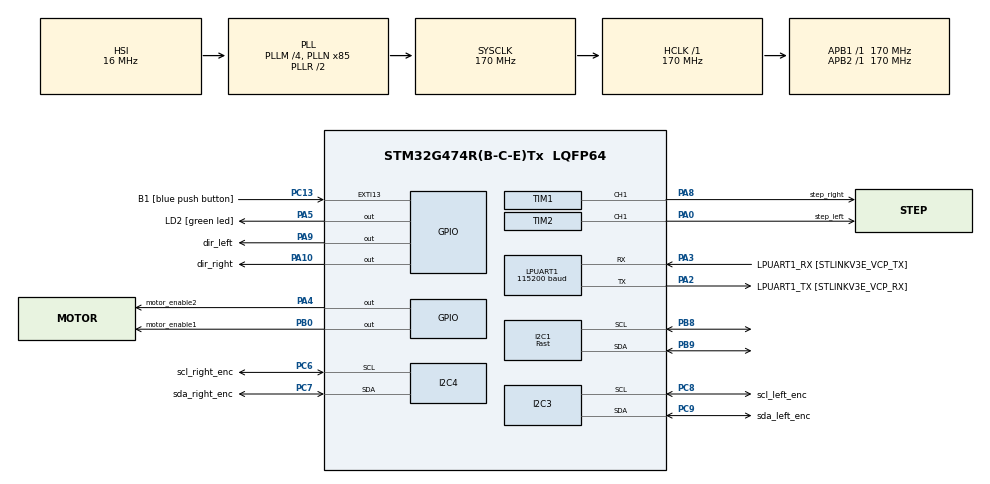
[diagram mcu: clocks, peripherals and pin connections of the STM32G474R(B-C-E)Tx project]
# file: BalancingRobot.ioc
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Dma.I2C1_RX.0.Direction=DMA_PERIPH_TO_MEMORY
Dma.I2C1_RX.0.EventEnable=DISABLE
Dma.I2C1_RX.0.Instance=DMA1_Channel1
Dma.I2C1_RX.0.MemDataAlignment=DMA_MDATAALIGN_BYTE
Dma.I2C1_RX.0.MemInc=DMA_MINC_ENABLE
Dma.I2C1_RX.0.Mode=DMA_NORMAL
Dma.I2C1_RX.0.PeriphDataAlignment=DMA_PDATAALIGN_BYTE
Dma.I2C1_RX.0.PeriphInc=DMA_PINC_DISABLE
Dma.I2C1_RX.0.Polarity=HAL_DMAMUX_REQ_GEN_RISING
Dma.I2C1_RX.0.Priority=DMA_PRIORITY_LOW
Dma.I2C1_RX.0.RequestNumber=1
Dma.I2C1_RX.0.SignalID=NONE
Dma.I2C1_RX.0.SyncEnable=DISABLE
Dma.I2C1_RX.0.SyncPolarity=HAL_DMAMUX_SYNC_NO_EVENT
Dma.I2C1_RX.0.SyncRequestNumber=1
Dma.I2C1_RX.0.SyncSignalID=NONE
Dma.LPUART1_RX.1.Direction=DMA_PERIPH_TO_MEMORY
Dma.LPUART1_RX.1.EventEnable=DISABLE
Dma.LPUART1_RX.1.Instance=DMA1_Channel2
Dma.LPUART1_RX.1.MemDataAlignment=DMA_MDATAALIGN_BYTE
Dma.LPUART1_RX.1.MemInc=DMA_MINC_ENABLE
Dma.LPUART1_RX.1.Mode=DMA_CIRCULAR
Dma.LPUART1_RX.1.PeriphDataAlignment=DMA_PDATAALIGN_BYTE
Dma.LPUART1_RX.1.PeriphInc=DMA_PINC_DISABLE
Dma.LPUART1_RX.1.Polarity=HAL_DMAMUX_REQ_GEN_RISING
Dma.LPUART1_RX.1.Priority=DMA_PRIORITY_LOW
Dma.LPUART1_RX.1.RequestNumber=1
Dma.LPUART1_RX.1.SignalID=NONE
Dma.LPUART1_RX.1.SyncEnable=DISABLE
Dma.LPUART1_RX.1.SyncPolarity=HAL_DMAMUX_SYNC_NO_EVENT
Dma.LPUART1_RX.1.SyncRequestNumber=1
Dma.LPUART1_RX.1.SyncSignalID=NONE
Dma.LPUART1_TX.2.Direction=DMA_MEMORY_TO_PERIPH
Dma.LPUART1_TX.2.EventEnable=DISABLE
Dma.LPUART1_TX.2.Instance=DMA1_Channel3
Dma.LPUART1_TX.2.MemDataAlignment=DMA_MDATAALIGN_BYTE
Dma.LPUART1_TX.2.MemInc=DMA_MINC_ENABLE
Dma.LPUART1_TX.2.Mode=DMA_NORMAL
Dma.LPUART1_TX.2.PeriphDataAlignment=DMA_PDATAALIGN_BYTE
Dma.LPUART1_TX.2.PeriphInc=DMA_PINC_DISABLE
Dma.LPUART1_TX.2.Polarity=HAL_DMAMUX_REQ_GEN_RISING
Dma.LPUART1_TX.2.Priority=DMA_PRIORITY_LOW
Dma.LPUART1_TX.2.RequestNumber=1
Dma.LPUART1_TX.2.SignalID=NONE
Dma.LPUART1_TX.2.SyncEnable=DISABLE
Dma.LPUART1_TX.2.SyncPolarity=HAL_DMAMUX_SYNC_NO_EVENT
Dma.LPUART1_TX.2.SyncRequestNumber=1
Dma.LPUART1_TX.2.SyncSignalID=NONE
Dma.Request0=I2C1_RX
Dma.Request1=LPUART1_RX
Dma.Request2=LPUART1_TX
I2C1.I2C_Speed_Mode=I2C_Fast
I2C1.Timing=0x10802D9B
I2C3.Timing=0x30A0A7FB
I2C4.Timing=0x30A0A7FB
IWDG.Prescaler=IWDG_PRESCALER_32
IWDG.Reload=99
IWDG.Window=4095
LPUART1.BaudRate=115200
LPUART1.WordLength=UART_WORDLENGTH_8B
Mcu.Family=STM32G4
Mcu.Name=STM32G474R(B-C-E)Tx
Mcu.Package=LQFP64
NVIC.DMA1_Channel1_IRQn=true\:2\:0\:true\:false\:true\:false\:true\:true
NVIC.DMA1_Channel2_IRQn=true\:3\:0\:true\:false\:true\:false\:true\:true
NVIC.DMA1_Channel3_IRQn=true\:3\:0\:true\:false\:true\:false\:true\:true
NVIC.EXTI15_10_IRQn=true\:4\:0\:true\:false\:true\:true\:true\:true
NVIC.I2C1_ER_IRQn=true\:2\:0\:true\:false\:true\:true\:true\:true
NVIC.I2C1_EV_IRQn=true\:2\:0\:true\:false\:true\:true\:true\:true
NVIC.I2C3_ER_IRQn=true\:3\:0\:true\:false\:true\:true\:true\:true
NVIC.I2C3_EV_IRQn=true\:3\:0\:true\:false\:true\:true\:true\:true
NVIC.I2C4_ER_IRQn=true\:3\:0\:true\:false\:true\:true\:true\:true
NVIC.I2C4_EV_IRQn=true\:3\:0\:true\:false\:true\:true\:true\:true
NVIC.LPUART1_IRQn=true\:3\:0\:true\:false\:true\:true\:true\:true
NVIC.PriorityGroup=NVIC_PRIORITYGROUP_4
NVIC.TIM6_DAC_IRQn=true\:1\:0\:true\:false\:true\:true\:true\:true
PA0.GPIO_Label=step_left
PA0.Signal=S_TIM2_CH1
PA10.GPIO_Label=dir_right
PA10.Signal=GPIO_Output
PA13.GPIO_Label=T_SWDIO
PA13.Mode=Serial_Wire
PA13.Signal=SYS_JTMS-SWDIO
PA14.GPIO_Label=T_SWCLK
PA14.Mode=Serial_Wire
PA14.Signal=SYS_JTCK-SWCLK
PA2.GPIO_Label=LPUART1_TX [STLINKV3E_VCP_RX]
PA2.Mode=Asynchronous
PA2.Signal=LPUART1_TX
PA3.GPIO_Label=LPUART1_RX [STLINKV3E_VCP_TX]
PA3.Mode=Asynchronous
PA3.Signal=LPUART1_RX
PA4.GPIO_Label=motor_enable2
PA4.Signal=GPIO_Output
PA5.GPIO_Label=LD2 [green led]
PA5.Signal=GPIO_Output
PA8.GPIO_Label=step_right
PA8.Signal=S_TIM1_CH1
PA9.GPIO_Label=dir_left
PA9.Signal=GPIO_Output
PB0.GPIO_Label=motor_enable1
PB0.PinState=GPIO_PIN_SET
PB0.Signal=GPIO_Output
PB3.GPIO_Label=T_SWO
PB3.Signal=SYS_JTDO-SWO
PB8-BOOT0.Mode=I2C
PB8-BOOT0.Signal=I2C1_SCL
PB9.Mode=I2C
PB9.Signal=I2C1_SDA
PC13.GPIO_Label=B1 [blue push button]
PC13.Signal=GPXTI13
PC14-OSC32_IN.Mode=LSE-External-Oscillator
PC14-OSC32_IN.Signal=RCC_OSC32_IN
PC15-OSC32_OUT.Mode=LSE-External-Oscillator
PC15-OSC32_OUT.Signal=RCC_OSC32_OUT
PC6.GPIO_Label=scl_right_enc
PC6.GPIO_Pu=GPIO_PULLUP
PC6.Mode=I2C
PC6.Signal=I2C4_SCL
PC7.GPIO_Label=sda_right_enc
PC7.GPIO_Pu=GPIO_PULLUP
PC7.Mode=I2C
PC7.Signal=I2C4_SDA
PC8.GPIO_Label=scl_left_enc
PC8.GPIO_Pu=GPIO_PULLUP
PC8.Mode=I2C
PC8.Signal=I2C3_SCL
PC9.GPIO_Label=sda_left_enc
PC9.GPIO_Pu=GPIO_PULLUP
PC9.Mode=I2C
PC9.Signal=I2C3_SDA
PF0-OSC_IN.Mode=HSE-External-Oscillator
PF0-OSC_IN.Signal=RCC_OSC_IN
PF1-OSC_OUT.Mode=HSE-External-Oscillator
PF1-OSC_OUT.Signal=RCC_OSC_OUT
ProjectManager.HeapSize=0x200
ProjectManager.StackSize=0x400
ProjectManager.TargetToolchain=STM32CubeIDE
RCC.ADC12Freq_Value=170000000
RCC.ADC345Freq_Value=170000000
RCC.AHBFreq_Value=170000000
RCC.APB1Freq_Value=170000000
RCC.APB1TimFreq_Value=170000000
RCC.APB2Freq_Value=170000000
RCC.APB2TimFreq_Value=170000000
RCC.CortexFreq_Value=170000000
RCC.EXTERNAL_CLOCK_VALUE=12288000
RCC.HCLKFreq_Value=170000000
RCC.HSE_VALUE=24000000
RCC.HSI48_VALUE=48000000
RCC.HSI_VALUE=16000000
RCC.PLLM=RCC_PLLM_DIV4
RCC.PLLN=85
RCC.RTCClockSelection=RCC_RTCCLKSOURCE_LSE
RCC.SYSCLKFreq_VALUE=170000000
RCC.SYSCLKSource=RCC_SYSCLKSOURCE_PLLCLK
RCC.USBFreq_Value=170000000
RCC.VCOOutputFreq_Value=340000000
SH.S_TIM1_CH1.0=TIM1_CH1,PWM Generation1 CH1
SH.S_TIM2_CH1.0=TIM2_CH1,PWM Generation1 CH1
TIM1.AutoReloadPreload=TIM_AUTORELOAD_PRELOAD_ENABLE
TIM1.Channel-PWM\ Generation1\ CH1=TIM_CHANNEL_1
TIM1.PeriodNoDither=999
TIM1.Prescaler=169
TIM2.AutoReloadPreload=TIM_AUTORELOAD_PRELOAD_ENABLE
TIM2.Channel-PWM\ Generation1\ CH1=TIM_CHANNEL_1
TIM2.PeriodNoDither=999
TIM2.Prescaler=169
TIM6.PeriodNoDither=1999
TIM6.Prescaler=169
VP_IWDG_VS_IWDG.Mode=IWDG_Activate
VP_SYS_VS_DBSignals.Mode=DisableDeadBatterySignals
VP_TIM1_VS_ClockSourceINT.Mode=Internal
VP_TIM2_VS_ClockSourceINT.Mode=Internal
VP_TIM6_VS_ClockSourceINT.Mode=Enable_Timer
board=NUCLEO-G474RE

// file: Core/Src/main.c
/* USER CODE BEGIN Header */
/**
  ******************************************************************************
  * @file           : main.c
  * @brief          : Main program body
  ******************************************************************************
  * @attention
  *
  * Copyright (c) 2026 STMicroelectronics.
  * All rights reserved.
  *
  * This software is licensed under terms that can be found in the LICENSE file
  * in the root directory of this software component.
  * If no LICENSE file comes with this software, it is provided AS-IS.
  *
  ******************************************************************************
  */
/* USER CODE END Header */
#include "main.h"

/* USER CODE BEGIN Includes */
#include "robot_app.h"

/* USER CODE END Includes */

I2C_HandleTypeDef hi2c1;
I2C_HandleTypeDef hi2c3;
I2C_HandleTypeDef hi2c4;
DMA_HandleTypeDef hdma_i2c1_rx;

IWDG_HandleTypeDef hiwdg;

UART_HandleTypeDef hlpuart1;
DMA_HandleTypeDef hdma_lpuart1_rx;
DMA_HandleTypeDef hdma_lpuart1_tx;

TIM_HandleTypeDef htim1;
TIM_HandleTypeDef htim2;
TIM_HandleTypeDef htim6;

void SystemClock_Config(void);
static void MX_GPIO_Init(void);
static void MX_DMA_Init(void);
static void MX_LPUART1_UART_Init(void);
static void MX_I2C1_Init(void);
static void MX_TIM1_Init(void);
static void MX_TIM6_Init(void);
static void MX_IWDG_Init(void);
static void MX_TIM2_Init(void);
static void MX_I2C3_Init(void);
static void MX_I2C4_Init(void);

int main(void)
{

  /* MCU Configuration--------------------------------------------------------*/

  /* Reset of all peripherals, Initializes the Flash interface and the Systick. */
  HAL_Init();

  /* Configure the system clock */
  SystemClock_Config();

  /* Initialize all configured peripherals */
  MX_GPIO_Init();
  MX_DMA_Init();
  MX_LPUART1_UART_Init();
  MX_I2C1_Init();
  MX_TIM1_Init();
  MX_TIM6_Init();
  MX_IWDG_Init();
  MX_TIM2_Init();
  MX_I2C3_Init();
  MX_I2C4_Init();
  /* USER CODE BEGIN 2 */
  if (Robot_App_Init() != HAL_OK)
  {
    Error_Handler();
  }

  /* USER CODE END 2 */

  /* Infinite loop */
  while (1)
  {

    /* USER CODE BEGIN 3 */
    Robot_App_Run();
  }
  /* USER CODE END 3 */
}

void SystemClock_Config(void)
{
  RCC_OscInitTypeDef RCC_OscInitStruct = {0};
  RCC_ClkInitTypeDef RCC_ClkInitStruct = {0};

  /** Configure the main internal regulator output voltage
  */
  HAL_PWREx_ControlVoltageScaling(PWR_REGULATOR_VOLTAGE_SCALE1_BOOST);
  /** Initializes the RCC Oscillators according to the specified parameters
  * in the RCC_OscInitTypeDef structure.
  */
  RCC_OscInitStruct.OscillatorType = RCC_OSCILLATORTYPE_HSI|RCC_OSCILLATORTYPE_LSI;
  RCC_OscInitStruct.HSIState = RCC_HSI_ON;
  RCC_OscInitStruct.HSICalibrationValue = RCC_HSICALIBRATION_DEFAULT;
  RCC_OscInitStruct.LSIState = RCC_LSI_ON;
  RCC_OscInitStruct.PLL.PLLState = RCC_PLL_ON;
  RCC_OscInitStruct.PLL.PLLSource = RCC_PLLSOURCE_HSI;
  RCC_OscInitStruct.PLL.PLLM = RCC_PLLM_DIV4;
  RCC_OscInitStruct.PLL.PLLN = 85;
  RCC_OscInitStruct.PLL.PLLP = RCC_PLLP_DIV2;
  RCC_OscInitStruct.PLL.PLLQ = RCC_PLLQ_DIV2;
  RCC_OscInitStruct.PLL.PLLR = RCC_PLLR_DIV2;
  if (HAL_RCC_OscConfig(&RCC_OscInitStruct) != HAL_OK)
  {
    Error_Handler();
  }
  /** Initializes the CPU, AHB and APB buses clocks
  */
  RCC_ClkInitStruct.ClockType = RCC_CLOCKTYPE_HCLK|RCC_CLOCKTYPE_SYSCLK
                              |RCC_CLOCKTYPE_PCLK1|RCC_CLOCKTYPE_PCLK2;
  RCC_ClkInitStruct.SYSCLKSource = RCC_SYSCLKSOURCE_PLLCLK;
  RCC_ClkInitStruct.AHBCLKDivider = RCC_SYSCLK_DIV1;
  RCC_ClkInitStruct.APB1CLKDivider = RCC_HCLK_DIV1;
  RCC_ClkInitStruct.APB2CLKDivider = RCC_HCLK_DIV1;

  if (HAL_RCC_ClockConfig(&RCC_ClkInitStruct, FLASH_LATENCY_4) != HAL_OK)
  {
    Error_Handler();
  }
}

static void MX_I2C1_Init(void)
{

  hi2c1.Instance = I2C1;
  hi2c1.Init.Timing = 0x10802D9B;
  hi2c1.Init.OwnAddress1 = 0;
  hi2c1.Init.AddressingMode = I2C_ADDRESSINGMODE_7BIT;
  hi2c1.Init.DualAddressMode = I2C_DUALADDRESS_DISABLE;
  hi2c1.Init.OwnAddress2 = 0;
  hi2c1.Init.OwnAddress2Masks = I2C_OA2_NOMASK;
  hi2c1.Init.GeneralCallMode = I2C_GENERALCALL_DISABLE;
  hi2c1.Init.NoStretchMode = I2C_NOSTRETCH_DISABLE;
  if (HAL_I2C_Init(&hi2c1) != HAL_OK)
  {
    Error_Handler();
  }
  /** Configure Analogue filter
  */
  if (HAL_I2CEx_ConfigAnalogFilter(&hi2c1, I2C_ANALOGFILTER_ENABLE) != HAL_OK)
  {
    Error_Handler();
  }
  /** Configure Digital filter
  */
  if (HAL_I2CEx_ConfigDigitalFilter(&hi2c1, 0) != HAL_OK)
  {
    Error_Handler();
  }

}

static void MX_I2C3_Init(void)
{

  hi2c3.Instance = I2C3;
  hi2c3.Init.Timing = 0x30A0A7FB;
  hi2c3.Init.OwnAddress1 = 0;
  hi2c3.Init.AddressingMode = I2C_ADDRESSINGMODE_7BIT;
  hi2c3.Init.DualAddressMode = I2C_DUALADDRESS_DISABLE;
  hi2c3.Init.OwnAddress2 = 0;
  hi2c3.Init.OwnAddress2Masks = I2C_OA2_NOMASK;
  hi2c3.Init.GeneralCallMode = I2C_GENERALCALL_DISABLE;
  hi2c3.Init.NoStretchMode = I2C_NOSTRETCH_DISABLE;
  if (HAL_I2C_Init(&hi2c3) != HAL_OK)
  {
    Error_Handler();
  }
  /** Configure Analogue filter
  */
  if (HAL_I2CEx_ConfigAnalogFilter(&hi2c3, I2C_ANALOGFILTER_ENABLE) != HAL_OK)
  {
    Error_Handler();
  }
  /** Configure Digital filter
  */
  if (HAL_I2CEx_ConfigDigitalFilter(&hi2c3, 0) != HAL_OK)
  {
    Error_Handler();
  }

}

static void MX_I2C4_Init(void)
{

  hi2c4.Instance = I2C4;
  hi2c4.Init.Timing = 0x30A0A7FB;
  hi2c4.Init.OwnAddress1 = 0;
  hi2c4.Init.AddressingMode = I2C_ADDRESSINGMODE_7BIT;
  hi2c4.Init.DualAddressMode = I2C_DUALADDRESS_DISABLE;
  hi2c4.Init.OwnAddress2 = 0;
  hi2c4.Init.OwnAddress2Masks = I2C_OA2_NOMASK;
  hi2c4.Init.GeneralCallMode = I2C_GENERALCALL_DISABLE;
  hi2c4.Init.NoStretchMode = I2C_NOSTRETCH_DISABLE;
  if (HAL_I2C_Init(&hi2c4) != HAL_OK)
  {
    Error_Handler();
  }
  /** Configure Analogue filter
  */
  if (HAL_I2CEx_ConfigAnalogFilter(&hi2c4, I2C_ANALOGFILTER_ENABLE) != HAL_OK)
  {
    Error_Handler();
  }
  /** Configure Digital filter
  */
  if (HAL_I2CEx_ConfigDigitalFilter(&hi2c4, 0) != HAL_OK)
  {
    Error_Handler();
  }

}

static void MX_IWDG_Init(void)
{

  hiwdg.Instance = IWDG;
  hiwdg.Init.Prescaler = IWDG_PRESCALER_32;
  hiwdg.Init.Window = 4095;
  hiwdg.Init.Reload = 99;
  if (HAL_IWDG_Init(&hiwdg) != HAL_OK)
  {
    Error_Handler();
  }

}

static void MX_LPUART1_UART_Init(void)
{

  hlpuart1.Instance = LPUART1;
  hlpuart1.Init.BaudRate = 115200;
  hlpuart1.Init.WordLength = UART_WORDLENGTH_8B;
  hlpuart1.Init.StopBits = UART_STOPBITS_1;
  hlpuart1.Init.Parity = UART_PARITY_NONE;
  hlpuart1.Init.Mode = UART_MODE_TX_RX;
  hlpuart1.Init.HwFlowCtl = UART_HWCONTROL_NONE;
  hlpuart1.Init.OneBitSampling = UART_ONE_BIT_SAMPLE_DISABLE;
  hlpuart1.Init.ClockPrescaler = UART_PRESCALER_DIV1;
  hlpuart1.AdvancedInit.AdvFeatureInit = UART_ADVFEATURE_NO_INIT;
  if (HAL_UART_Init(&hlpuart1) != HAL_OK)
  {
    Error_Handler();
  }
  if (HAL_UARTEx_SetTxFifoThreshold(&hlpuart1, UART_TXFIFO_THRESHOLD_1_8) != HAL_OK)
  {
    Error_Handler();
  }
  if (HAL_UARTEx_SetRxFifoThreshold(&hlpuart1, UART_RXFIFO_THRESHOLD_1_8) != HAL_OK)
  {
    Error_Handler();
  }
  if (HAL_UARTEx_DisableFifoMode(&hlpuart1) != HAL_OK)
  {
    Error_Handler();
  }

}

static void MX_TIM1_Init(void)
{

  TIM_ClockConfigTypeDef sClockSourceConfig = {0};
  TIM_MasterConfigTypeDef sMasterConfig = {0};
  TIM_OC_InitTypeDef sConfigOC = {0};
  TIM_BreakDeadTimeConfigTypeDef sBreakDeadTimeConfig = {0};

  htim1.Instance = TIM1;
  htim1.Init.Prescaler = 169;
  htim1.Init.CounterMode = TIM_COUNTERMODE_UP;
  htim1.Init.Period = 999;
  htim1.Init.ClockDivision = TIM_CLOCKDIVISION_DIV1;
  htim1.Init.RepetitionCounter = 0;
  htim1.Init.AutoReloadPreload = TIM_AUTORELOAD_PRELOAD_ENABLE;
  if (HAL_TIM_Base_Init(&htim1) != HAL_OK)
  {
    Error_Handler();
  }
  sClockSourceConfig.ClockSource = TIM_CLOCKSOURCE_INTERNAL;
  if (HAL_TIM_ConfigClockSource(&htim1, &sClockSourceConfig) != HAL_OK)
  {
    Error_Handler();
  }
  if (HAL_TIM_PWM_Init(&htim1) != HAL_OK)
  {
    Error_Handler();
  }
  sMasterConfig.MasterOutputTrigger = TIM_TRGO_RESET;
  sMasterConfig.MasterOutputTrigger2 = TIM_TRGO2_RESET;
  sMasterConfig.MasterSlaveMode = TIM_MASTERSLAVEMODE_DISABLE;
  if (HAL_TIMEx_MasterConfigSynchronization(&htim1, &sMasterConfig) != HAL_OK)
  {
    Error_Handler();
  }
  sConfigOC.OCMode = TIM_OCMODE_PWM1;
  sConfigOC.Pulse = 0;
  sConfigOC.OCPolarity = TIM_OCPOLARITY_HIGH;
  sConfigOC.OCNPolarity = TIM_OCNPOLARITY_HIGH;
  sConfigOC.OCFastMode = TIM_OCFAST_DISABLE;
  sConfigOC.OCIdleState = TIM_OCIDLESTATE_RESET;
  sConfigOC.OCNIdleState = TIM_OCNIDLESTATE_RESET;
  if (HAL_TIM_PWM_ConfigChannel(&htim1, &sConfigOC, TIM_CHANNEL_1) != HAL_OK)
  {
    Error_Handler();
  }
  sBreakDeadTimeConfig.OffStateRunMode = TIM_OSSR_DISABLE;
  sBreakDeadTimeConfig.OffStateIDLEMode = TIM_OSSI_DISABLE;
  sBreakDeadTimeConfig.LockLevel = TIM_LOCKLEVEL_OFF;
  sBreakDeadTimeConfig.DeadTime = 0;
  sBreakDeadTimeConfig.BreakState = TIM_BREAK_DISABLE;
  sBreakDeadTimeConfig.BreakPolarity = TIM_BREAKPOLARITY_HIGH;
  sBreakDeadTimeConfig.BreakFilter = 0;
  sBreakDeadTimeConfig.BreakAFMode = TIM_BREAK_AFMODE_INPUT;
  sBreakDeadTimeConfig.Break2State = TIM_BREAK2_DISABLE;
  sBreakDeadTimeConfig.Break2Polarity = TIM_BREAK2POLARITY_HIGH;
  sBreakDeadTimeConfig.Break2Filter = 0;
  sBreakDeadTimeConfig.Break2AFMode = TIM_BREAK_AFMODE_INPUT;
  sBreakDeadTimeConfig.AutomaticOutput = TIM_AUTOMATICOUTPUT_DISABLE;
  if (HAL_TIMEx_ConfigBreakDeadTime(&htim1, &sBreakDeadTimeConfig) != HAL_OK)
  {
    Error_Handler();
  }
  HAL_TIM_MspPostInit(&htim1);

}

static void MX_TIM2_Init(void)
{

  TIM_ClockConfigTypeDef sClockSourceConfig = {0};
  TIM_MasterConfigTypeDef sMasterConfig = {0};
  TIM_OC_InitTypeDef sConfigOC = {0};

  htim2.Instance = TIM2;
  htim2.Init.Prescaler = 169;
  htim2.Init.CounterMode = TIM_COUNTERMODE_UP;
  htim2.Init.Period = 999;
  htim2.Init.ClockDivision = TIM_CLOCKDIVISION_DIV1;
  htim2.Init.AutoReloadPreload = TIM_AUTORELOAD_PRELOAD_ENABLE;
  if (HAL_TIM_Base_Init(&htim2) != HAL_OK)
  {
    Error_Handler();
  }
  sClockSourceConfig.ClockSource = TIM_CLOCKSOURCE_INTERNAL;
  if (HAL_TIM_ConfigClockSource(&htim2, &sClockSourceConfig) != HAL_OK)
  {
    Error_Handler();
  }
  if (HAL_TIM_PWM_Init(&htim2) != HAL_OK)
  {
    Error_Handler();
  }
  sMasterConfig.MasterOutputTrigger = TIM_TRGO_RESET;
  sMasterConfig.MasterSlaveMode = TIM_MASTERSLAVEMODE_DISABLE;
  if (HAL_TIMEx_MasterConfigSynchronization(&htim2, &sMasterConfig) != HAL_OK)
  {
    Error_Handler();
  }
  sConfigOC.OCMode = TIM_OCMODE_PWM1;
  sConfigOC.Pulse = 0;
  sConfigOC.OCPolarity = TIM_OCPOLARITY_HIGH;
  sConfigOC.OCFastMode = TIM_OCFAST_DISABLE;
  if (HAL_TIM_PWM_ConfigChannel(&htim2, &sConfigOC, TIM_CHANNEL_1) != HAL_OK)
  {
    Error_Handler();
  }
  HAL_TIM_MspPostInit(&htim2);

}

static void MX_TIM6_Init(void)
{

  TIM_MasterConfigTypeDef sMasterConfig = {0};

  htim6.Instance = TIM6;
  htim6.Init.Prescaler = 169;
  htim6.Init.CounterMode = TIM_COUNTERMODE_UP;
  htim6.Init.Period = 1999;
  htim6.Init.AutoReloadPreload = TIM_AUTORELOAD_PRELOAD_DISABLE;
  if (HAL_TIM_Base_Init(&htim6) != HAL_OK)
  {
    Error_Handler();
  }
  sMasterConfig.MasterOutputTrigger = TIM_TRGO_RESET;
  sMasterConfig.MasterSlaveMode = TIM_MASTERSLAVEMODE_DISABLE;
  if (HAL_TIMEx_MasterConfigSynchronization(&htim6, &sMasterConfig) != HAL_OK)
  {
    Error_Handler();
  }

}

static void MX_DMA_Init(void)
{

  /* DMA controller clock enable */
  __HAL_RCC_DMAMUX1_CLK_ENABLE();
  __HAL_RCC_DMA1_CLK_ENABLE();

  /* DMA interrupt init */
  /* DMA1_Channel1_IRQn interrupt configuration */
  HAL_NVIC_SetPriority(DMA1_Channel1_IRQn, 2, 0);
  HAL_NVIC_EnableIRQ(DMA1_Channel1_IRQn);
  /* DMA1_Channel2_IRQn interrupt configuration */
  HAL_NVIC_SetPriority(DMA1_Channel2_IRQn, 3, 0);
  HAL_NVIC_EnableIRQ(DMA1_Channel2_IRQn);
  /* DMA1_Channel3_IRQn interrupt configuration */
  HAL_NVIC_SetPriority(DMA1_Channel3_IRQn, 3, 0);
  HAL_NVIC_EnableIRQ(DMA1_Channel3_IRQn);

}

static void MX_GPIO_Init(void)
{
  GPIO_InitTypeDef GPIO_InitStruct = {0};

  /* GPIO Ports Clock Enable */
  __HAL_RCC_GPIOC_CLK_ENABLE();
  __HAL_RCC_GPIOF_CLK_ENABLE();
  __HAL_RCC_GPIOA_CLK_ENABLE();
  __HAL_RCC_GPIOB_CLK_ENABLE();

  /*Configure GPIO pin Output Level */
  HAL_GPIO_WritePin(GPIOA, motor_enable2_Pin|LD2_Pin|dir_left_Pin|dir_right_Pin, GPIO_PIN_RESET);

  /*Configure GPIO pin Output Level */
  HAL_GPIO_WritePin(motor_enable1_GPIO_Port, motor_enable1_Pin, GPIO_PIN_SET);

  /*Configure GPIO pin : B1_Pin */
  GPIO_InitStruct.Pin = B1_Pin;
  GPIO_InitStruct.Mode = GPIO_MODE_IT_RISING;
  GPIO_InitStruct.Pull = GPIO_NOPULL;
  HAL_GPIO_Init(B1_GPIO_Port, &GPIO_InitStruct);

  /*Configure GPIO pins : motor_enable2_Pin LD2_Pin dir_left_Pin dir_right_Pin */
  GPIO_InitStruct.Pin = motor_enable2_Pin|LD2_Pin|dir_left_Pin|dir_right_Pin;
  GPIO_InitStruct.Mode = GPIO_MODE_OUTPUT_PP;
  GPIO_InitStruct.Pull = GPIO_NOPULL;
  GPIO_InitStruct.Speed = GPIO_SPEED_FREQ_LOW;
  HAL_GPIO_Init(GPIOA, &GPIO_InitStruct);

  /*Configure GPIO pin : motor_enable1_Pin */
  GPIO_InitStruct.Pin = motor_enable1_Pin;
  GPIO_InitStruct.Mode = GPIO_MODE_OUTPUT_PP;
  GPIO_InitStruct.Pull = GPIO_NOPULL;
  GPIO_InitStruct.Speed = GPIO_SPEED_FREQ_LOW;
  HAL_GPIO_Init(motor_enable1_GPIO_Port, &GPIO_InitStruct);

  /* EXTI interrupt init*/
  HAL_NVIC_SetPriority(EXTI15_10_IRQn, 4, 0);
  HAL_NVIC_EnableIRQ(EXTI15_10_IRQn);

}

void Error_Handler(void)
{
  __disable_irq();
  while (1)
  {
  }
}
